# PIC16F18877 register map
File version: 1.0
Registers are 8-bit, read-write, reset 0x0 unless marked. A register's access mark holds for its fields unless they carry their own. Offsets are from the block's base; [hi:lo] are bit positions; {n}, {i} and the like mark numbered series.

## NVM — Flash and EEPROM access
Base 0x00800796
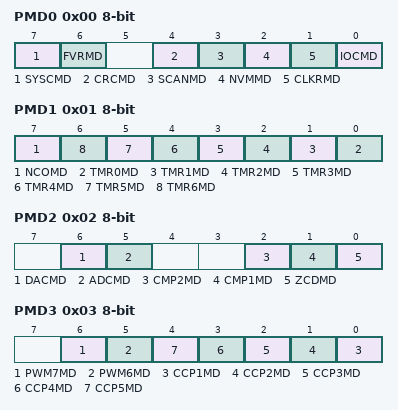
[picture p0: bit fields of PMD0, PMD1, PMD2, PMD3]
0x00 PMD0 — PMD0, data address 0x796
  [7] SYSCMD, [6] FVRMD, [4] CRCMD, [3] SCANMD, [2] NVMMD, [1] CLKRMD, [0] IOCMD
0x01 PMD1 — PMD1, data address 0x797
  [7] NCOMD, [n] TMR{n}MD (n=0..6)
0x02 PMD2 — PMD2, data address 0x798
  [6] DACMD, [5] ADCMD, [2] CMP2MD, [1] CMP1MD, [0] ZCDMD
0x03 PMD3 — PMD3, data address 0x799
  [6] PWM7MD, [5] PWM6MD, [n-1] CCP{n}MD (n=1..5)
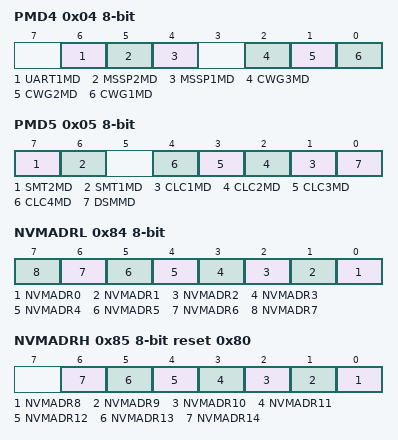
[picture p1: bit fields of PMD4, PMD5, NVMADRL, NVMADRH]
0x04 PMD4 — PMD4, data address 0x79a
  [6] UART1MD, [5] MSSP2MD, [4] MSSP1MD, [2] CWG3MD, [1] CWG2MD, [0] CWG1MD
0x05 PMD5 — PMD5, data address 0x79b
  [7] SMT2MD, [6] SMT1MD, [n] CLC{n}MD (n=1..4), [0] DSMMD
0x84 NVMADRL — NVMADRL, data address 0x81a
  [n] NVMADR{n} (n=0..7)
0x85 NVMADRH reset 0x80 — NVMADRH, data address 0x81b
  [n-8] NVMADR{n} (n=8..14)
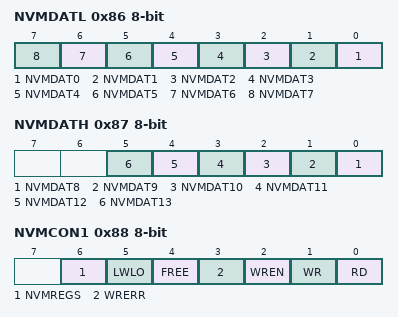
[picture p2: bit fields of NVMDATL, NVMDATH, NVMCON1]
0x86 NVMDATL — NVMDATL, data address 0x81c
  [n] NVMDAT{n} (n=0..7)
0x87 NVMDATH — NVMDATH, data address 0x81d
  [n-8] NVMDAT{n} (n=8..13)
0x88 NVMCON1 — NVMCON1, data address 0x81e
  [6] NVMREGS, [5] LWLO, [4] FREE, [3] WRERR, [2] WREN, [1] WR, [0] RD
0x89 NVMCON2 — NVMCON2, data address 0x81f

## OSCILLATOR
Base 0x0080088D
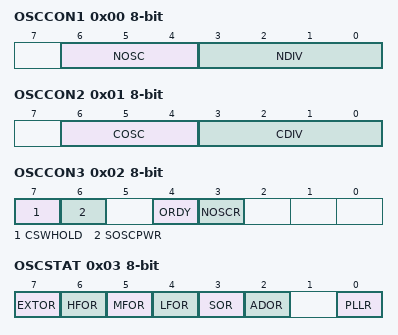
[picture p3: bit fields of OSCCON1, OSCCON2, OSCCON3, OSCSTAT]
0x00 OSCCON1 (reset mask 0xF) — OSCCON1, data address 0x88d
  [6:4] NOSC, [3:0] NDIV
0x01 OSCCON2 reset not defined — OSCCON2, data address 0x88e
  [6:4] COSC, [3:0] CDIV
0x02 OSCCON3 — OSCCON3, data address 0x88f
  [7] CSWHOLD, [6] SOSCPWR, [4] ORDY, [3] NOSCR
0x03 OSCSTAT (reset mask 0x71) — OSCSTAT, data address 0x890
  [7] EXTOR, [6] HFOR, [5] MFOR, [4] LFOR, [3] SOR, [2] ADOR, [0] PLLR
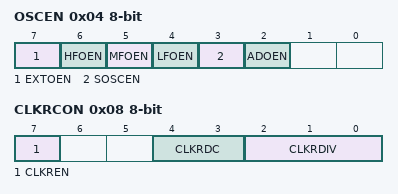
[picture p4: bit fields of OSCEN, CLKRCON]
0x04 OSCEN — OSCEN, data address 0x891
  [7] EXTOEN, [6] HFOEN, [5] MFOEN, [4] LFOEN, [3] SOSCEN, [2] ADOEN
0x05 OSCTUNE reset 0x20 — OSCTUNE, data address 0x892
  [5:0] HFTUN
0x06 OSCFRQ reset not defined — OSCFRQ, data address 0x893
  [2:0] HFFRQ
0x08 CLKRCON (reset mask 0x80) — CLKRCON, data address 0x895
  [7] CLKREN, [4:3] CLKRDC, [2:0] CLKRDIV
0x09 CLKRCLK — CLKRCLK, data address 0x896
  [3:0] CLKRCLK

## PORTA
Base 0x0080000C
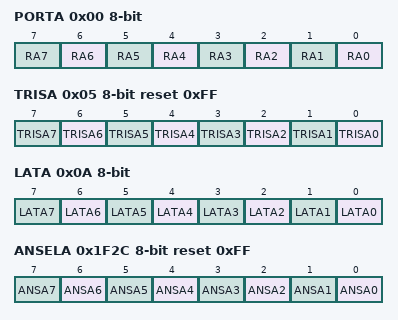
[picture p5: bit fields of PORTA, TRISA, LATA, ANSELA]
0x00 PORTA reset not defined — PORTA, data address 0x00c
  [n] RA{n} (n=0..7)
0x05 TRISA reset 0xFF — TRISA, data address 0x011
  [n] TRISA{n} (n=0..7)
0x0A LATA reset not defined — LATA, data address 0x016
  [n] LATA{n} (n=0..7)
0x1F2C ANSELA reset 0xFF — ANSELA, data address 0x1f38
  [n] ANSA{n} (n=0..7)
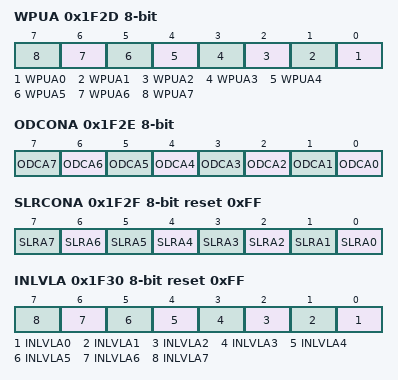
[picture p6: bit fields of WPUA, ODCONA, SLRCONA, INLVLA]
0x1F2D WPUA — WPUA, data address 0x1f39
  [n] WPUA{n} (n=0..7)
0x1F2E ODCONA — ODCONA, data address 0x1f3a
  [n] ODCA{n} (n=0..7)
0x1F2F SLRCONA reset 0xFF — SLRCONA, data address 0x1f3b
  [n] SLRA{n} (n=0..7)
0x1F30 INLVLA reset 0xFF — INLVLA, data address 0x1f3c
  [n] INLVLA{n} (n=0..7)
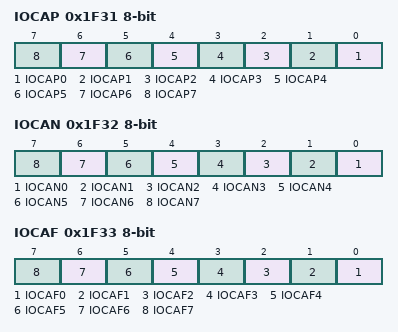
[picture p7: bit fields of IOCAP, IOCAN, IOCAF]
0x1F31 IOCAP — IOCAP, data address 0x1f3d
  [n] IOCAP{n} (n=0..7)
0x1F32 IOCAN — IOCAN, data address 0x1f3e
  [n] IOCAN{n} (n=0..7)
0x1F33 IOCAF — IOCAF, data address 0x1f3f
  [n] IOCAF{n} (n=0..7)

## PORTB
Base 0x0080000D
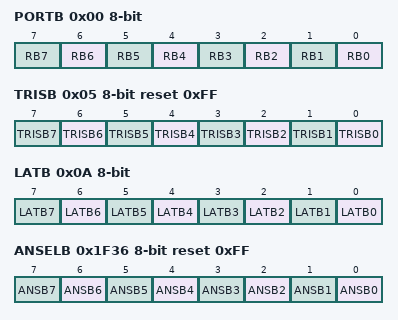
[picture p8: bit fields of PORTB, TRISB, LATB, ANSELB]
0x00 PORTB reset not defined — PORTB, data address 0x00d
  [n] RB{n} (n=0..7)
0x05 TRISB reset 0xFF — TRISB, data address 0x012
  [n] TRISB{n} (n=0..7)
0x0A LATB reset not defined — LATB, data address 0x017
  [n] LATB{n} (n=0..7)
0x1F36 ANSELB reset 0xFF — ANSELB, data address 0x1f43
  [n] ANSB{n} (n=0..7)
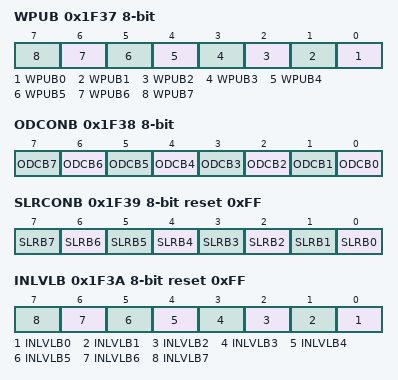
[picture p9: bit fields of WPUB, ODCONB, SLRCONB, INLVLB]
0x1F37 WPUB — WPUB, data address 0x1f44
  [n] WPUB{n} (n=0..7)
0x1F38 ODCONB — ODCONB, data address 0x1f45
  [n] ODCB{n} (n=0..7)
0x1F39 SLRCONB reset 0xFF — SLRCONB, data address 0x1f46
  [n] SLRB{n} (n=0..7)
0x1F3A INLVLB reset 0xFF — INLVLB, data address 0x1f47
  [n] INLVLB{n} (n=0..7)
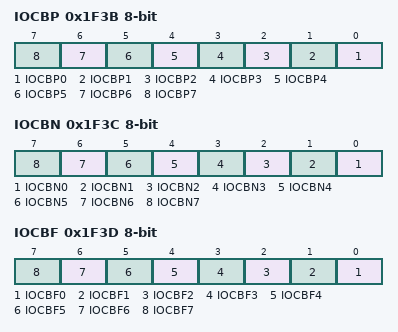
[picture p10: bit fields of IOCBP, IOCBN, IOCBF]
0x1F3B IOCBP — IOCBP, data address 0x1f48
  [n] IOCBP{n} (n=0..7)
0x1F3C IOCBN — IOCBN, data address 0x1f49
  [n] IOCBN{n} (n=0..7)
0x1F3D IOCBF — IOCBF, data address 0x1f4a
  [n] IOCBF{n} (n=0..7)

## PORTC
Base 0x0080000E
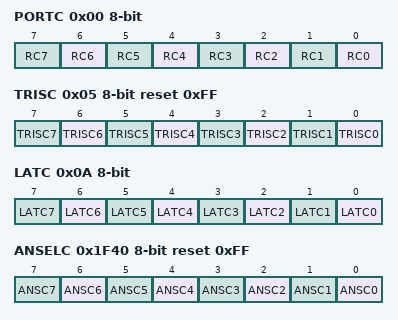
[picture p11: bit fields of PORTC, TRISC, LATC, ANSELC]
0x00 PORTC reset not defined — PORTC, data address 0x00e
  [n] RC{n} (n=0..7)
0x05 TRISC reset 0xFF — TRISC, data address 0x013
  [n] TRISC{n} (n=0..7)
0x0A LATC reset not defined — LATC, data address 0x018
  [n] LATC{n} (n=0..7)
0x1F40 ANSELC reset 0xFF — ANSELC, data address 0x1f4e
  [n] ANSC{n} (n=0..7)
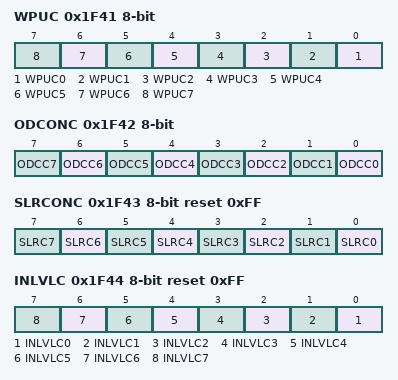
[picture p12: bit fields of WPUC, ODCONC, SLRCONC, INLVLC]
0x1F41 WPUC — WPUC, data address 0x1f4f
  [n] WPUC{n} (n=0..7)
0x1F42 ODCONC — ODCONC, data address 0x1f50
  [n] ODCC{n} (n=0..7)
0x1F43 SLRCONC reset 0xFF — SLRCONC, data address 0x1f51
  [n] SLRC{n} (n=0..7)
0x1F44 INLVLC reset 0xFF — INLVLC, data address 0x1f52
  [n] INLVLC{n} (n=0..7)
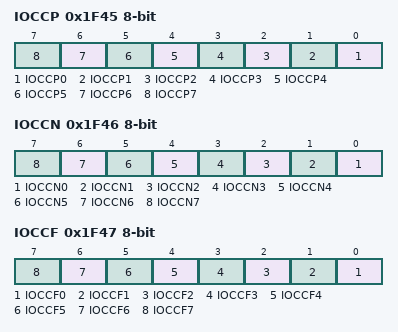
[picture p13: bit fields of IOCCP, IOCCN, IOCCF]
0x1F45 IOCCP — IOCCP, data address 0x1f53
  [n] IOCCP{n} (n=0..7)
0x1F46 IOCCN — IOCCN, data address 0x1f54
  [n] IOCCN{n} (n=0..7)
0x1F47 IOCCF — IOCCF, data address 0x1f55
  [n] IOCCF{n} (n=0..7)
